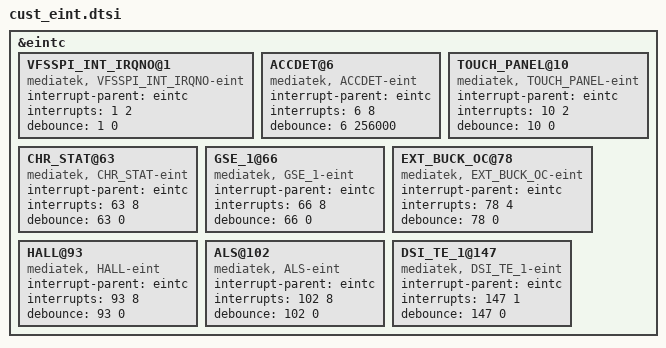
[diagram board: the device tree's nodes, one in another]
/*
 * Generated by MTK SP DrvGen Version 03.13.6 for MT6753. Copyright MediaTek Inc. (C) 2013.
 * Mon Aug 10 11:19:05 2015
 * Do Not Modify the File.
 */

/*************************
 * EINT DTSI File
*************************/

&eintc {
	VFSSPI_INT_IRQNO@1 {
		compatible = "mediatek, VFSSPI_INT_IRQNO-eint";
		interrupt-parent = <&eintc>;
		interrupts = <1 2>;
		debounce = <1 0>;
	};

	ACCDET@6 {
		compatible = "mediatek, ACCDET-eint";
		interrupt-parent = <&eintc>;
		interrupts = <6 8>;
		debounce = <6 256000>;
	};

	TOUCH_PANEL@10 {
		compatible = "mediatek, TOUCH_PANEL-eint";
		interrupt-parent = <&eintc>;
		interrupts = <10 2>;
		debounce = <10 0>;
	};

	CHR_STAT@63 {
		compatible = "mediatek, CHR_STAT-eint";
		interrupt-parent = <&eintc>;
		interrupts = <63 8>;
		debounce = <63 0>;
	};

	GSE_1@66 {
		compatible = "mediatek, GSE_1-eint";
		interrupt-parent = <&eintc>;
		interrupts = <66 8>;
		debounce = <66 0>;
	};

	EXT_BUCK_OC@78 {
		compatible = "mediatek, EXT_BUCK_OC-eint";
		interrupt-parent = <&eintc>;
		interrupts = <78 4>;
		debounce = <78 0>;
	};

	HALL@93 {
		compatible = "mediatek, HALL-eint";
		interrupt-parent = <&eintc>;
		interrupts = <93 8>;
		debounce = <93 0>;
	};

	ALS@102 {
		compatible = "mediatek, ALS-eint";
		interrupt-parent = <&eintc>;
		interrupts = <102 8>;
		debounce = <102 0>;
	};

	DSI_TE_1@147 {
		compatible = "mediatek, DSI_TE_1-eint";
		interrupt-parent = <&eintc>;
		interrupts = <147 1>;
		debounce = <147 0>;
	};

};
